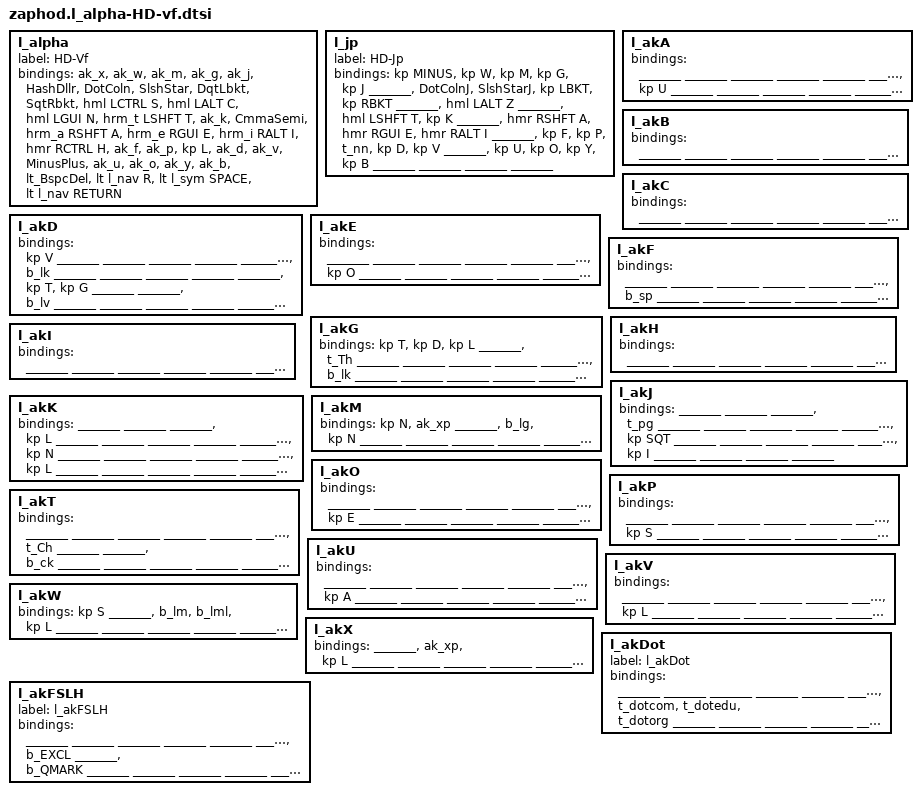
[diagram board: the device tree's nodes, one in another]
#define _______  &trans

/*  Base (alpha) Layer  Hands Down Vibranium-vf
    Building for a 36/42 key board
     ╭─────────────────────╮ ╭──────────────────────╮
     │  X   W   M   G   J  │ │  #$  .:  /*  "[  ']  │
     │  S   C   N   T   K  | |  ,;   A   E   I   H  │
     │  F   P   L   D   V  │ │  -+   U   O   Y   B  │ RSFT
     ╰──────╮  App BSP  R  │ │  SPC RET TAB  ╭──────╯
            ╰──────────────╯ ╰───────────────╯
*/


                    l_alpha {
                        label = "HD-Vf";
                        bindings = <
&ak_x    &ak_w      &ak_m     &ak_g     &ak_j         &HashDllr  &DotColn    &SlshStar   &DqtLbkt   &SqtRbkt
&hml LCTRL S &hml LALT C   &hml LGUI N  &hrm_t LSHFT T &ak_k     &CmmaSemi   &hrm_a RSHFT A &hrm_e RGUI E  &hrm_i RALT I  &hmr RCTRL H
&ak_f    &ak_p      &kp L     &ak_d     &ak_v         &MinusPlus &ak_u       &ak_o       &ak_y      &ak_b
                    &lt_BspcDel    &lt l_nav R        &lt l_sym SPACE   &lt l_nav RETURN
                        >;
                    };
            l_jp {
                label = "HD-Jp"; // Japanese "mode" (L, C, X not used in Japanese, so repurpose to -, Z, ん)
                bindings = <
          &kp MINUS &kp W      &kp M   &kp G         &kp J      _______    &DotColnJ    &SlshStarJ   &kp LBKT    &kp RBKT
          _______   &hml LALT Z _______ &hml LSHFT T &kp K      _______    &hmr RSHFT A &hmr RGUI E  &hmr RALT I _______
          &kp F     &kp P      &t_nn   &kp D         &kp V      _______    &kp U        &kp O        &kp Y       &kp B
                                       _______     _______      _______    _______
                >;
            };
            l_akA {
//                label = "l_akA";
                bindings = <
          _______   _______   _______   _______   _______       _______   _______   _______   _______   _______
          _______   _______   _______   _______   _______       _______   _______   &kp U     _______   _______
          _______   _______   _______   _______   _______       _______   _______   _______   _______   _______
                                        _______   _______       _______   _______
                >;
            };
            l_akB {
//                label = "l_akB";
                bindings = <
          _______   _______   _______   _______   _______       _______   _______   _______   _______   _______
          _______   _______   _______   _______   _______       _______   _______   _______   _______   _______
          _______   _______   _______   _______   _______       _______   _______   _______   _______   _______
                                        _______   _______       _______   _______
                >;
            };
            l_akC {
//                label = "l_akC";
                bindings = <
          _______   _______   _______   _______   _______       _______   _______   _______   _______   _______
          _______   _______   _______   _______   _______       _______   _______   _______   _______   _______
          _______   _______   _______   _______   _______       _______   _______   _______   _______   _______
                                        _______   _______       _______   _______
                >;
            };
            l_akD {
//                label = "l_akD";
                bindings = <
          &kp V     _______   _______   _______   _______       _______   _______   _______   _______   _______
          _______   _______   _______   _______   &b_lk         _______   _______   _______   _______   _______
          &kp T     &kp G     _______   _______   &b_lv         _______   _______   _______   _______   _______
                                        _______   _______       _______   _______
                >;
            };
            l_akE {
//                label = "l_akE";
                bindings = <
          _______   _______   _______   _______   _______       _______   _______   _______   _______   _______
          _______   _______   _______   _______   _______       _______   _______   _______   _______   &kp O
          _______   _______   _______   _______   _______       _______   _______   _______   _______   _______
                                        _______   _______       _______   _______
                >;
            };
            l_akF {
//                label = "l_akF";
                bindings = <
          _______   _______   _______   _______   _______       _______   _______   _______   _______   _______
          _______   _______   _______   _______   _______       _______   _______   _______   _______   _______
          _______   &b_sp     _______   _______   _______       _______   _______   _______   _______   _______
                                        _______   _______       _______   _______
                >;
            };
            l_akG {
//                label = "l_akG";
                bindings = <
          &kp T     &kp D     &kp L     _______   &t_Th         _______   _______   _______   _______   _______
          _______   _______   _______   _______   &b_lk         _______   _______   _______   _______   _______
          _______   _______   _______   _______   _______       _______   _______   _______   _______   _______
                                        _______   _______       _______   _______
                    >;
            };
            l_akH {
//                label = "l_akH";
                bindings = <
          _______   _______   _______   _______   _______       _______   _______   _______   _______   _______
          _______   _______   _______   _______   _______       _______   _______   _______   _______   _______
          _______   _______   _______   _______   _______       _______   _______   _______   _______   _______
                                        _______   _______       _______   _______
                >;
            };
            l_akI {
//                label = "l_akI";
                bindings = <
          _______   _______   _______   _______   _______       _______   _______   _______   _______   _______
          _______   _______   _______   _______   _______       _______   _______   _______   _______   _______
          _______   _______   _______   _______   _______       _______   _______   _______   _______   _______
                                        _______   _______       _______   _______
                >;
            };
            l_akJ { // using l_akJ for Y as well
//                label = "l_akJ";
                bindings = <
          _______   _______   _______   &t_pg     _______       _______   _______   _______   _______   _______
          _______   _______   _______   _______   _______       _______   _______   _______   _______   &kp SQT
          _______   _______   _______   _______   _______       _______   _______   _______   _______   &kp I
                                        _______   _______       _______   _______
                >;
            };
            l_akK {
//                label = "l_akK";
                bindings = <
          _______   _______   _______   &kp L     _______       _______   _______   _______   _______   _______
          _______   _______   _______   &kp N     _______       _______   _______   _______   _______   _______
          _______   _______   _______   &kp L     _______       _______   _______   _______   _______   _______
                                        _______   _______       _______   _______
                    >;
            };
            l_akM {
//                label = "l_akM";
                bindings = <
          &kp N    &ak_xp     _______   &b_lg     &kp N         _______   _______   _______   _______   _______
          _______   _______   _______   _______   _______       _______   _______   _______   _______   _______
          _______   _______   _______   _______   _______       _______   _______   _______   _______   _______
                                        _______   _______       _______   _______
                >;
            };
            l_akO {
//                label = "l_akO";
                bindings = <
          _______   _______   _______   _______   _______       _______   _______   _______   _______   _______
          _______   _______   _______   _______   _______       _______   _______   _______   _______   &kp E
          _______   _______   _______   _______   _______       _______   _______   _______   _______   _______
                                        _______   _______       _______   _______
                >;
            };
            l_akP {
//                label = "l_akP";
                bindings = <
          _______   _______   _______   _______   _______       _______   _______   _______   _______   _______
          _______   _______   _______   _______   _______       _______   _______   _______   _______   _______
          &kp S     _______   _______   _______   _______       _______   _______   _______   _______   _______
                                        _______   _______       _______   _______
                >;
            };
            l_akT {
//                label = "l_akT";
                bindings = <
          _______   _______   _______   _______   _______       _______   _______   _______   _______   _______
          _______   &t_Ch     _______   _______   &b_ck         _______   _______   _______   _______   _______
          _______   _______   _______   _______   _______       _______   _______   _______   _______   _______
                                        _______   _______       _______   _______
                >;
            };
            l_akU {
//                label = "l_akU";
                bindings = <
          _______   _______   _______   _______   _______       _______   _______   _______   _______   _______
          _______   _______   _______   _______   _______       _______   _______   _______   _______   &kp A
          _______   _______   _______   _______   _______       _______   _______   _______   _______   _______
                                        _______   _______       _______   _______
                >;
            };
            l_akV {
//                label = "l_akV";
                bindings = <
          _______   _______   _______   _______   _______       _______   _______   _______   _______   _______
          _______   _______   _______   _______   _______       _______   _______   _______   _______   _______
          _______   _______   _______   &kp L     _______       _______   _______   _______   _______   _______
                                        _______   _______       _______   _______
                >;
            };
            l_akW {
//                label = "l_akW";
                bindings = <
          &kp S     _______   &b_lm     &b_lml    &kp L         _______   _______   _______   _______   _______
          _______   _______   _______   _______   _______       _______   _______   _______   _______   _______
          _______   _______   _______   _______   _______       _______   _______   _______   _______   _______
                                        _______   _______       _______   _______
                >;
            };
            l_akX {
//                label = "l_akX";
                bindings = <
          _______   &ak_xp    &kp L     _______   _______       _______   _______   _______   _______   _______
          _______   _______   _______   _______   _______       _______   _______   _______   _______   _______
          _______   _______   _______   _______   _______       _______   _______   _______   _______   _______
                                        _______   _______       _______   _______
                >;
            };

                   l_akDot {
                        label = "l_akDot";
                        bindings = <
_______   _______   _______   _______   _______       _______   _______   &t_dotcom &t_dotedu &t_dotorg
_______   _______   _______   _______   _______       _______   _______   _______   _______   _______
_______   _______   _______   _______   _______       _______   _______   _______   _______   _______
                              _______   _______       _______   _______
                            >;
                   };
                l_akFSLH {
                        label = "l_akFSLH";
                        bindings = <

_______   _______   _______   _______   _______       _______   &b_EXCL   _______  &b_QMARK   _______
_______   _______   _______   _______   _______       _______   _______   _______   _______   _______
_______   _______   _______   _______   _______       _______   _______   _______   _______   _______
                              _______   _______       _______   _______
                        >;
                };
